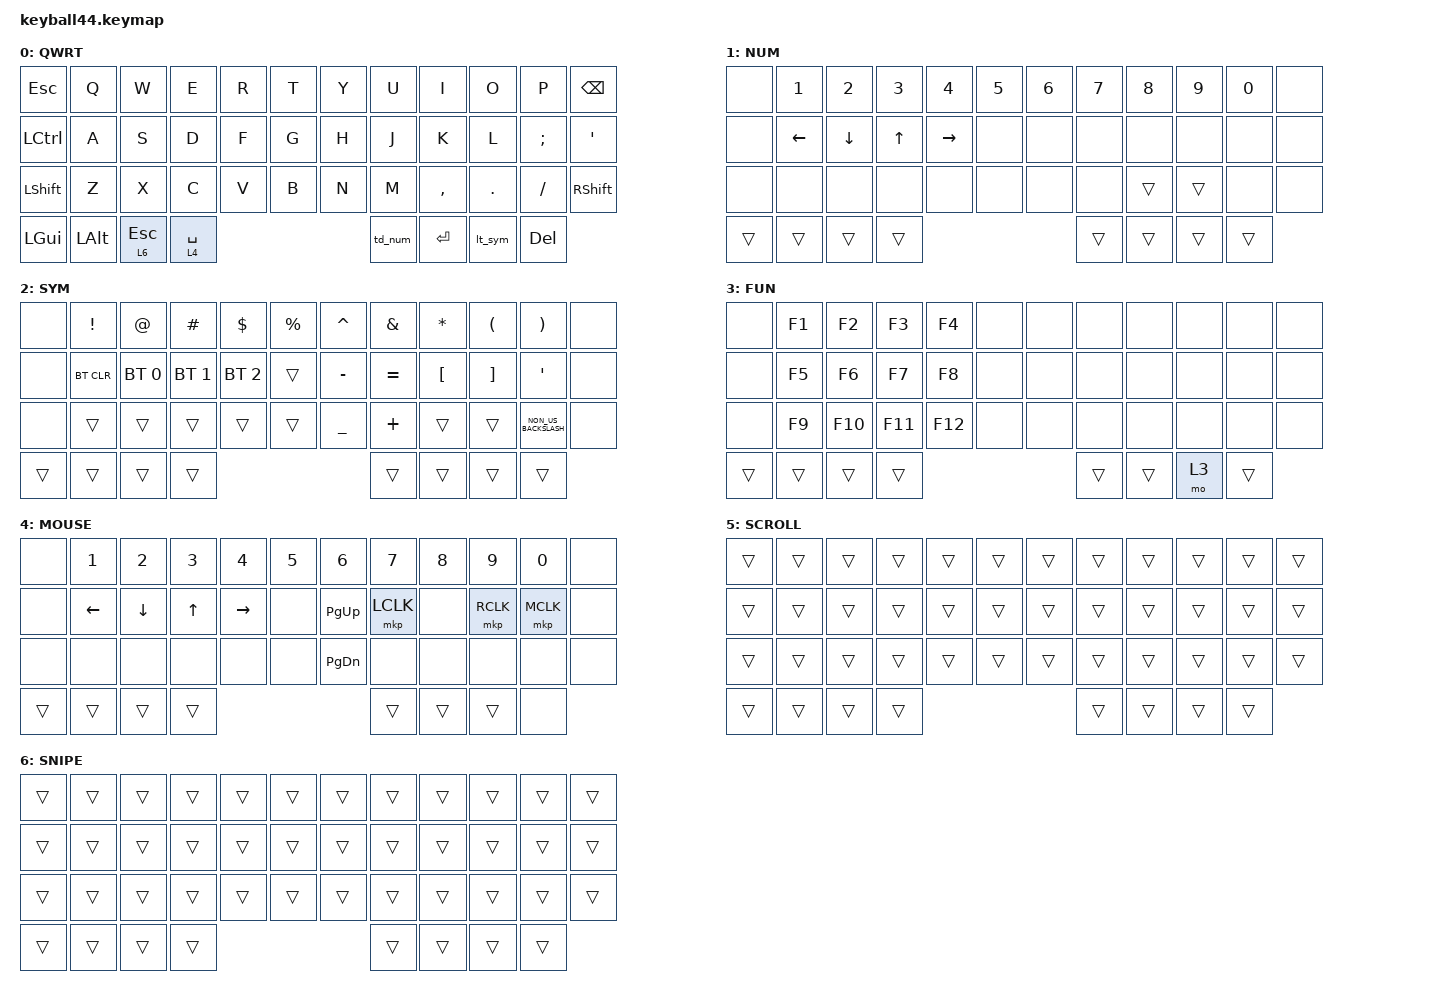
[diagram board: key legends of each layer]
#define DEFAULT 0
#define NUM     1
#define SYM     2
#define FUN     3
#define MOUSE   4
#define SCROLL  5
#define SNIPE   6

#include <behaviors/mouse_keys.dtsi>
#include <behaviors.dtsi>
#include <dt-bindings/zmk/bt.h>
#include <dt-bindings/zmk/keys.h>
#include <dt-bindings/zmk/mouse.h>
#include <dt-bindings/zmk/rgb.h>

&lt {
    tapping-term-ms = <240>;
    flavor = "balanced";
    quick-tap-ms = <150>;
};

&mt {
    tapping-term-ms = <200>;
    flavor = "tap-preferred";
    quick-tap-ms = <150>;
};

&caps_word { continue-list = <UNDERSCORE MINUS>; };

/ {
    // custom shift using mod-morph 

    behaviors {
        cmqus: comma_question {
            compatible = "zmk,behavior-mod-morph";
            label = "COMMA_QUESTION";
            #binding-cells = <0>;
            bindings = <&kp COMMA>, <&kp QUESTION>;

            mods = <(MOD_LSFT|MOD_RSFT)>;
        };

        dtsmi: dot_semi {
            compatible = "zmk,behavior-mod-morph";
            label = "DOT_SEMI";
            #binding-cells = <0>;
            bindings = <&kp DOT>, <&kp SEMI>;

            mods = <(MOD_LSFT|MOD_RSFT)>;
        };

        // ── Tap-Dance: 1 tap = momentary NUM (layer 1), 2 taps = toggle NUM ──────
        td_num: tap_dance_num {
            compatible = "zmk,behavior-tap-dance";
            #binding-cells = <0>;
            tapping-term-ms = <200>;
            bindings = <&mo NUM>, <&tog NUM>;
        };

        // ── Tap-Dance: 1 tap = momentary SYM (layer 2), 2 taps = toggle SYM ──────
        td_sym: tap_dance_sym {
            compatible = "zmk,behavior-tap-dance";
            #binding-cells = <0>;
            tapping-term-ms = <200>;
            bindings = <&mo SYM>, <&tog SYM>;
        };
        
        // Drop-in replacement for &lt 2 <key>
        // Usage in keymap: &lt_sym BACKSPACE
        lt_sym: lt_sym {
            compatible = "zmk,behavior-hold-tap";
            #binding-cells = <1>;           // 1 cell = the tap keycode only
            tapping-term-ms = <200>;
            flavor = "tap-preferred";
            quick-tap-ms = <150>;
            bindings = <&mo_sym_rgb>, <&kp>;
        };

        // Drop-in replacement for any &lt 1 <key> or &mo 1 key
        // Usage in keymap: &lt_num SOME_KEY
        lt_num: lt_num {
            compatible = "zmk,behavior-hold-tap";
            #binding-cells = <1>;
            tapping-term-ms = <200>;
            flavor = "tap-preferred";
            quick-tap-ms = <150>;
            bindings = <&mo_num_rgb>, <&kp>;
        };
    };

    keymap {
        compatible = "zmk,keymap";

        default_layer {
            label = "QWRT";
            bindings = <
&kp ESCAPE      &kp Q     &kp W         &kp E        &kp R      &kp T                 &kp Y            &kp U  &kp I      &kp O    &kp P      &kp BACKSPACE
&kp LCTRL       &kp A     &kp S         &kp D        &kp F      &kp G                 &kp H            &kp J  &kp K      &kp L    &kp SEMI   &kp SQT
&kp LEFT_SHIFT  &kp Z     &kp X         &kp C        &kp V      &kp B                 &kp N            &kp M  &kp COMMA  &kp DOT  &kp SLASH  &kp RIGHT_SHIFT
&kp LGUI        &kp LALT  &lt 6 ESCAPE  &lt 4 SPACE  &td_num             &kp ENTER  &lt_sym                                        &kp DELETE
            >;
        };

        number_layer {
            label = "NUM";
            bindings = <
&none   &kp NUMBER_1  &kp NUMBER_2  &kp NUMBER_3  &kp NUMBER_4  &kp NUMBER_5              &kp NUMBER_6  &kp NUMBER_7  &kp NUMBER_8  &kp NUMBER_9  &kp NUMBER_0  &none
&none   &kp LEFT      &kp DOWN      &kp UP_ARROW  &kp RIGHT     &none                     &none         &none         &none         &none         &none         &none
&none   &none         &none         &none         &none         &none                     &none         &none         &trans        &trans        &none         &none
&trans  &trans        &trans        &trans        &trans                          &trans  &trans                                                                &trans
            >;
        };

        symbol_layer {
            label = "SYM";
            bindings = <
&none   &kp EXCLAMATION  &kp AT_SIGN   &kp HASH      &kp DOLLAR    &kp PERCENT              &kp CARET       &kp AMPERSAND  &kp ASTERISK      &kp LEFT_PARENTHESIS  &kp RIGHT_PARENTHESIS  &none
&none   &bt BT_CLR       &bt BT_SEL 0  &bt BT_SEL 1  &bt BT_SEL 2  &trans                   &kp MINUS       &kp EQUAL      &kp LEFT_BRACKET  &kp RIGHT_BRACKET     &kp SQT                &none
&none   &trans           &trans        &trans        &trans        &trans                   &kp UNDERSCORE  &kp PLUS       &trans            &trans                &kp NON_US_BACKSLASH   &none
&trans  &trans           &trans        &trans        &trans                         &trans  &trans                                                                                        &trans
            >;
        };

        function_layer {
            label = "FUN";
            bindings = <
&none   &kp F1  &kp F2   &kp F3   &kp F4   &none              &none  &none  &none  &none  &none  &none
&none   &kp F5  &kp F6   &kp F7   &kp F8   &none              &none  &none  &none  &none  &none  &none
&none   &kp F9  &kp F10  &kp F11  &kp F12  &none              &none  &none  &none  &none  &none  &none
&trans  &trans  &trans   &trans   &trans              &trans  &mo 3                              &trans
            >;
        };

        mouse_layer {
            label = "MOUSE";
            bindings = <
&none   &kp N1          &kp N2          &kp N3        &kp N4     &kp N5              &kp N6         &kp N7     &kp N8  &kp N9     &kp N0     &none
&none   &kp LEFT_ARROW  &kp DOWN_ARROW  &kp UP_ARROW  &kp RIGHT  &none               &kp PAGE_UP    &mkp LCLK  &none   &mkp RCLK  &mkp MCLK  &none
&none   &none           &none           &none         &none      &none               &kp PAGE_DOWN  &none      &none   &none      &none      &none
&trans  &trans          &trans          &trans        &trans                 &trans  &trans                                                  &none
            >;
        };

        scroll_layer {
            label = "SCROLL";
            bindings = <
&trans  &trans  &trans  &trans  &trans  &trans              &trans  &trans  &trans  &trans  &trans  &trans
&trans  &trans  &trans  &trans  &trans  &trans              &trans  &trans  &trans  &trans  &trans  &trans
&trans  &trans  &trans  &trans  &trans  &trans              &trans  &trans  &trans  &trans  &trans  &trans
&trans  &trans  &trans  &trans  &trans              &trans  &trans                                  &trans
            >;
        };

        snipe_layer {
            label = "SNIPE";
            bindings = <
&trans  &trans  &trans  &trans  &trans  &trans              &trans  &trans  &trans  &trans  &trans  &trans
&trans  &trans  &trans  &trans  &trans  &trans              &trans  &trans  &trans  &trans  &trans  &trans
&trans  &trans  &trans  &trans  &trans  &trans              &trans  &trans  &trans  &trans  &trans  &trans
&trans  &trans  &trans  &trans  &trans              &trans  &trans                                  &trans
            >;
        };
    };

    macros {

        // ── Layer 0: sparkle, #00ccff ─────────────────────────────────────────
        rgb_l0: rgb_l0 {
            compatible = "zmk,behavior-macro";
            #binding-cells = <0>;
            wait-ms = <0>;
            tap-ms  = <0>;
            bindings = <&macro_tap &rgb_ug RGB_COLOR_HSB(195, 100, 100)>;
        };

        rgb_l1: rgb_l1 {
            compatible = "zmk,behavior-macro";
            #binding-cells = <0>;
            wait-ms = <0>;
            tap-ms  = <0>;
            bindings = <&macro_tap &rgb_ug RGB_COLOR_HSB(195, 100, 100)>;
        };

        rgb_l2: rgb_l2 {
            compatible = "zmk,behavior-macro";
            #binding-cells = <0>;
            wait-ms = <0>;
            tap-ms  = <0>;
            bindings = <&macro_tap &rgb_ug RGB_COLOR_HSB(0, 100, 40)>;
        };

        // ── Momentary SYM (layer 2) hold: sets dark red, restores l0 on release
        mo_sym_rgb: mo_sym_rgb {
            compatible = "zmk,behavior-macro";
            #binding-cells = <0>;
            wait-ms = <0>;
            tap-ms  = <0>;
            bindings =
                <&macro_press   &mo SYM>,
                <&macro_tap     &rgb_l2>,
                <&macro_pause_for_release>,
                <&macro_release &mo SYM>,
                <&macro_tap     &rgb_l0>;
        };

        // ── Momentary NUM (layer 1) hold: sets solid cyan, restores l0 on release
        mo_num_rgb: mo_num_rgb {
            compatible = "zmk,behavior-macro";
            #binding-cells = <0>;
            wait-ms = <0>;
            tap-ms  = <0>;
            bindings =
                <&macro_press   &mo NUM>,
                <&macro_tap     &rgb_l1>,
                <&macro_pause_for_release>,
                <&macro_release &mo NUM>,
                <&macro_tap     &rgb_l0>;
        };
    };
};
